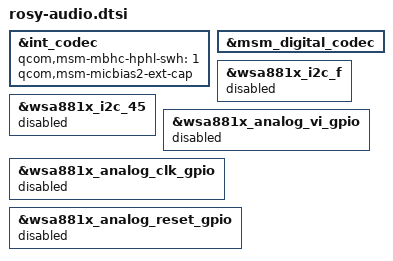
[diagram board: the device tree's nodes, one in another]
/*
 * Copyright (c) 2015-2016, 2018, 2020, The Linux Foundation. All rights reserved.
 * Copyright (C) 2019 XiaoMi, Inc.
 *
 * This program is free software; you can redistribute it and/or modify
 * it under the terms of the GNU General Public License version 2 and
 * only version 2 as published by the Free Software Foundation.
 *
 * This program is distributed in the hope that it will be useful,
 * but WITHOUT ANY WARRANTY; without even the implied warranty of
 * MERCHANTABILITY or FITNESS FOR A PARTICULAR PURPOSE.  See the
 * GNU General Public License for more details.
 */

&int_codec {
	qcom,msm-mbhc-hphl-swh = <1>;
	qcom,msm-micbias2-ext-cap;

	/delete-property/ qcom,cdc-us-euro-gpios;
	/delete-property/ asoc-wsa-codec-names;
	/delete-property/ asoc-wsa-codec-prefixes;
	/delete-property/ msm-vdd-wsa-switch-supply;
	/delete-property/ qcom,msm-vdd-wsa-switch-voltage;
	/delete-property/ qcom,msm-vdd-wsa-switch-current;
};

&msm_digital_codec {
	status = "ok";
};

&wsa881x_i2c_f {
        status = "disabled";
};

&wsa881x_i2c_45 {
        status = "disabled";
};

&wsa881x_analog_vi_gpio {
        status = "disabled";
};

&wsa881x_analog_clk_gpio {
        status = "disabled";
};

&wsa881x_analog_reset_gpio {
        status = "disabled";
};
